# DSS_TOP register map
Vendor: Texas Instruments
Peripheral module from a debugger description file (folder am437x).
Registers are 32-bit, read-only, no defined reset value unless marked. A register's access mark holds for its fields unless they carry their own. Offsets are as the file gives them; lines under a group give offsets from that group; [hi:lo] are bit positions; {n}, {i} and the like mark numbered series; 'fields as' and 'values as' point back to an identical list; <NAME> marks a mode.

## DSS_TOP
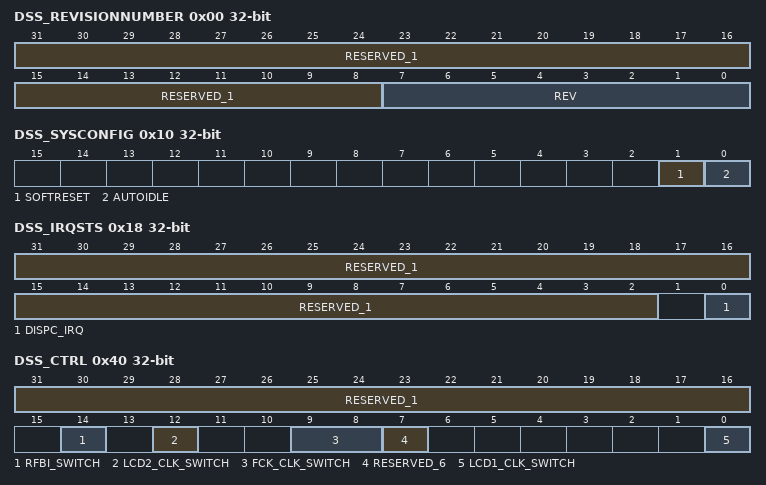
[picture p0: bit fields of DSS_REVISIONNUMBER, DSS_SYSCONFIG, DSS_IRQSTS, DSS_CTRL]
0x00 DSS_REVISIONNUMBER — This register contains the DisplaySubSystem revision number
  [31:8] RESERVED_1 — Reads returns 0
  [7:0] REV — [[br]][7:4] Major Revision [[br]][3:0] Minor revision
0x10 DSS_SYSCONFIG rw
  [1] SOFTRESET — Software Reset. [[br]]Set this bit to 1 to trigger a module reset. [[br]]The bit is automatically reset by the hardware. [[br]]During reads, it alwatys returns 0.
    1=en_2_0x1 (The module is reset.); 0=en_1_0x0 (Normal Mode.)
  [0] AUTOIDLE — Enable Power management capability
    1=en_2_0x1 (Automatic OCP clock gating strategy is applied on the OCP interface activity.); 0=en_1_0x0 (OCP clock is free running.)
0x14 DSS_SYSSTS
  [0] RESETDONE — Internal Reset monitoring.
    1=en_2_0x1 (Reset Completed); 0=en_1_0x0 (Internal module reset is ongoing.)
0x18 DSS_IRQSTS — This register indicates the source of the interrupt and the status of the interrupt line.
  [31:2] RESERVED_1 — Reads return 0s.
  [0] DISPC_IRQ — DISPC interrupt status
    1=en_2_0x1 (Interrupt active); 0=en_1_0x0 (Interrupt inactive)
0x40 DSS_CTRL rw
  [31:16] RESERVED_1 — Write 0's for suture compatibility.
  [14] RFBI_SWITCH — Selects the Video port from DISPC between Video port #1 and Video port #2 (mux #10)
    1=en_2_0x1 (Video Port #2 (also named secondary LCD output or LCD2) is selected.); 0=en_1_0x0 (Video Port #1 (also named primary LCD output or LCD1) is selected (backward compatibility mode))
  [12] LCD2_CLK_SWITCH — DSS_CLK/PLL2_CLK1 clock switch (mux #3). [[br]]Selects the clock source for the DISPC LCD2_CLK clock.
    1=en_2_0x1 (PLL2_CLK1 selected.); 0=en_1_0x0 (DSS_CLK selected (from PRCM))
  [9:8] FCK_CLK_SWITCH — Selects the clock source for the DISPC functional clock.
    3=en_4_0x3 (PLL3_CLK1 selected (from HDMI PLL)); 2=en_3_0x2 (PLL2_CLK1 selected (from DSI2 PLL)); 1=en_2_0x1 (PLL1_CLK1 selected (from DSI1_PLL)); 0=en_1_0x0 (DSS_CLK selected (from PRCM))
  [7] RESERVED_6 — Write 0's for suture compatibility.
  [0] LCD1_CLK_SWITCH — DSS_CLK/PLL1_CLK1 clock switch (mux #2). [[br]]Selects the clock source for the DISPC LCD1_CLK clock.
    1=en_2_0x1 (PLL1_CLK1 selected (from DSI1_PLL)); 0=en_1_0x0 (DSS_CLK selected (from PRCM))
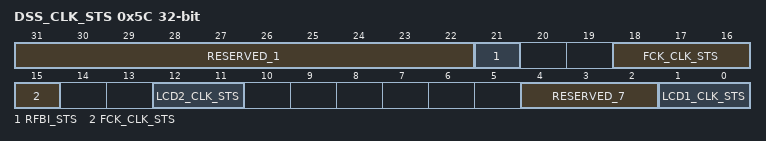
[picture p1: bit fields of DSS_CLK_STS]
0x5C DSS_CLK_STS
  [31:22] RESERVED_1 — Read returns 0.
  [21] RFBI_STS — Video port selection status (mux #11) Indiactes if video port #1 or video port #2 from DISPC is used to provide data to the RFBI.
    1=en_2_0x1 (Video Port #2 (named also secondary LCD output or LCD2) used to provide data to RFBI); 0=en_1_0x0 (Video Port #1 (named also as primary LCD output or LCD1) used to provide data to RFBI)
  [18:15] FCK_CLK_STS — FCK_CLK clock selection status (mux #1) indicates which clock is used by the glitch free mux selecting the source of FCK_CLK. [[br]]It is required to have the current clock and the new selected clock being running in order to be able to switch. [[br]]Both clocks are used at the same time while the switch is on going.
    8=en_5_0x8 (PLL3_CLK1 (TV_CLK) is used by DISPC as FCK_CLK clock); 4=en_4_0x4 (PLL2_CLK1 is used by DISPC as FCK_CLK clock); 2=en_3_0x2 (PLL1_CLK1 is used by DISPC as FCK_CLK clock); 1=en_2_0x1 (DSS_CLK is used by DISPC as FCK_CLK clock); 0=en_1_0x0 (DSS_CLK clock switch is ongoing)
  [12:11] LCD2_CLK_STS — LCD2_CLK clock selection status (mux #3) indicates which clock is used by the glitch free mux selecting the source of LCD2_CLK. [[br]]It is required for the current clock and the new selected clock being running in order to be able to switch. [[br]]Both clocks are are used at the same time while the switch is on going.
    2=en_3_0x2 (PLL2_CLK2 is used by DISPC as LCD2_CLK clock); 1=en_2_0x1 (DSS_CLK is used by DSI1 as LCD2_CLK clock); 0=en_1_0x0 (LCD2_CLK clock switch is ongoing)
  [4:2] RESERVED_7 — Read returns 0.
  [1:0] LCD1_CLK_STS — LCD1_CLK clock selection status (mux #2) indicates which clock is used by the glitch free mux selecting the source of LCD1_CLK. [[br]]It is required for the current clock and the new selected clock being running in order to be able to switch. [[br]]Both clocks are are used at the same time while the switch is on going.
    2=en_3_0x2 (PLl1_CLK1 is used by DISPC as LCD1_CLK); 1=en_2_0x1 (DSS_CLK is used as LCD1_CLK); 0=en_1_0x0 (LCD1_CLK clock switching is ongoing)
